AUTOSAR XML (schema 4-2-2)
package /STELLANTIS/EPT/ASWCs
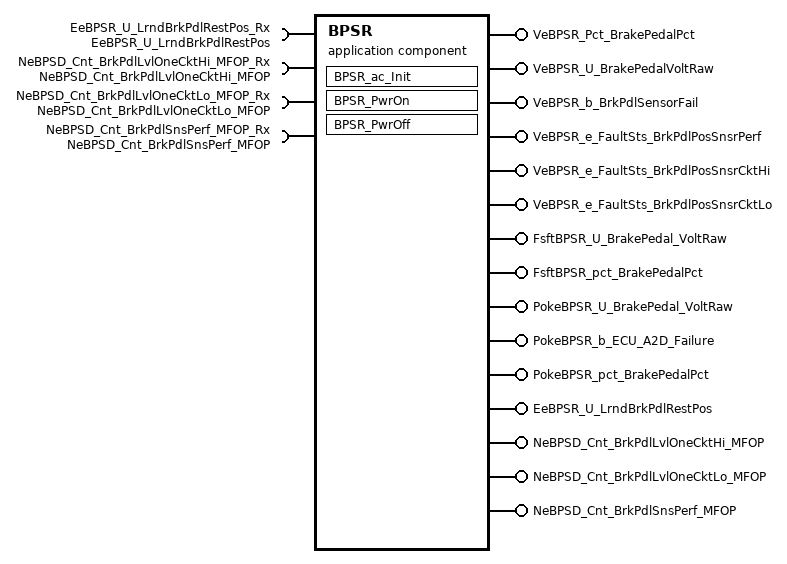
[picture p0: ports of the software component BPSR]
  application sw component type BPSR
    11 x provide port:
      VeBPSR_Pct_BrakePedalPct: nonqueued-sender-com-spec{data-element=Value, init-value=0}, provided-interface=VeBPSR_Pct_BrakePedalPct
      VeBPSR_U_BrakePedalVoltRaw: nonqueued-sender-com-spec{data-element=Value, init-value=0}, provided-interface=VeBPSR_U_BrakePedalVoltRaw
      VeBPSR_b_BrkPdlSensorFail: nonqueued-sender-com-spec{data-element=Value, init-value=0}, provided-interface=VeBPSR_b_BrkPdlSensorFail
      VeBPSR_e_FaultSts_BrkPdlPosSnsrPerf: nonqueued-sender-com-spec{data-element=Value, init-value=CeDFIB_e_Init}, provided-interface=VeBPSR_e_FaultSts_BrkPdlPosSnsrPerf
      VeBPSR_e_FaultSts_BrkPdlPosSnsrCktHi: nonqueued-sender-com-spec{data-element=Value, init-value=CeDFIB_e_Init}, provided-interface=VeBPSR_e_FaultSts_BrkPdlPosSnsrCktHi
      VeBPSR_e_FaultSts_BrkPdlPosSnsrCktLo: nonqueued-sender-com-spec{data-element=Value, init-value=CeDFIB_e_Init}, provided-interface=VeBPSR_e_FaultSts_BrkPdlPosSnsrCktLo
      FsftBPSR_U_BrakePedal_VoltRaw: server-com-spec=FsftBPSR_U_BrakePedal_VoltRaw, provided-interface=FsftBPSR_U_BrakePedal_VoltRaw
      FsftBPSR_pct_BrakePedalPct: server-com-spec=FsftBPSR_pct_BrakePedalPct, provided-interface=FsftBPSR_pct_BrakePedalPct
      PokeBPSR_U_BrakePedal_VoltRaw: server-com-spec{operation=PokeBPSR_U_BrakePedal_VoltRaw, queue-length=1}, provided-interface=PokeBPSR_U_BrakePedal_VoltRaw
      PokeBPSR_b_ECU_A2D_Failure: server-com-spec{operation=PokeBPSR_b_ECU_A2D_Failure, queue-length=1}, provided-interface=PokeBPSR_b_ECU_A2D_Failure
      PokeBPSR_pct_BrakePedalPct: server-com-spec{operation=PokeBPSR_pct_BrakePedalPct, queue-length=1}, provided-interface=PokeBPSR_pct_BrakePedalPct
    4 x require port:
      EeBPSR_U_LrndBrkPdlRestPos_Rx: nv-require-com-spec{init-value=20, variable=EeBPSR_U_LrndBrkPdlRestPos}, required-interface=EeBPSR_U_LrndBrkPdlRestPos
      NeBPSD_Cnt_BrkPdlLvlOneCktHi_MFOP_Rx: nv-require-com-spec{init-value=0, variable=NeBPSD_Cnt_BrkPdlLvlOneCktHi_MFOP}, required-interface=NeBPSD_Cnt_BrkPdlLvlOneCktHi_MFOP
      NeBPSD_Cnt_BrkPdlLvlOneCktLo_MFOP_Rx: nv-require-com-spec{init-value=0, variable=NeBPSD_Cnt_BrkPdlLvlOneCktLo_MFOP}, required-interface=NeBPSD_Cnt_BrkPdlLvlOneCktLo_MFOP
      NeBPSD_Cnt_BrkPdlSnsPerf_MFOP_Rx: nv-require-com-spec{init-value=0, variable=NeBPSD_Cnt_BrkPdlSnsPerf_MFOP}, required-interface=NeBPSD_Cnt_BrkPdlSnsPerf_MFOP
    4 x provide port:
      EeBPSR_U_LrndBrkPdlRestPos: nv-provide-com-spec{ram-block-init-value=20, variable=EeBPSR_U_LrndBrkPdlRestPos}, provided-interface=EeBPSR_U_LrndBrkPdlRestPos
      NeBPSD_Cnt_BrkPdlLvlOneCktHi_MFOP: nv-provide-com-spec{ram-block-init-value=0, variable=NeBPSD_Cnt_BrkPdlLvlOneCktHi_MFOP}, provided-interface=NeBPSD_Cnt_BrkPdlLvlOneCktHi_MFOP
      NeBPSD_Cnt_BrkPdlLvlOneCktLo_MFOP: nv-provide-com-spec{ram-block-init-value=0, variable=NeBPSD_Cnt_BrkPdlLvlOneCktLo_MFOP}, provided-interface=NeBPSD_Cnt_BrkPdlLvlOneCktLo_MFOP
      NeBPSD_Cnt_BrkPdlSnsPerf_MFOP: nv-provide-com-spec{ram-block-init-value=0, variable=NeBPSD_Cnt_BrkPdlSnsPerf_MFOP}, provided-interface=NeBPSD_Cnt_BrkPdlSnsPerf_MFOP
    behavior IB_BPSR: data-type-mapping=msADTtoIDTMapping, handle-termination-and-restart=NO-SUPPORT, included-data-type-set=data-type=TeBPSR_e_BrakeStatus
      init event Event_BPSR_ac_Init: start-on-event=BPSR_ac_Init
      init event Event_PwrOn: start-on-event=BPSR_PwrOn
      init event Event_PwrOff: start-on-event=BPSR_PwrOff
      runnable BPSR_ac_Init
        data-send-points:
          6 x access:
            OUT_VeBPSR_Pct_BrakePedalPct_Value: accessed-variable=VeBPSR_Pct_BrakePedalPct.Value
            OUT_VeBPSR_U_BrakePedalVoltRaw_Value: accessed-variable=VeBPSR_U_BrakePedalVoltRaw.Value
            OUT_VeBPSR_b_BrkPdlSensorFail_Value: accessed-variable=VeBPSR_b_BrkPdlSensorFail.Value
            OUT_VeBPSR_e_FaultSts_BrkPdlPosSnsrPerf_Value: accessed-variable=VeBPSR_e_FaultSts_BrkPdlPosSnsrPerf.Value
            OUT_VeBPSR_e_FaultSts_BrkPdlPosSnsrCktHi_Value: accessed-variable=VeBPSR_e_FaultSts_BrkPdlPosSnsrCktHi.Value
            OUT_VeBPSR_e_FaultSts_BrkPdlPosSnsrCktLo_Value: accessed-variable=VeBPSR_e_FaultSts_BrkPdlPosSnsrCktLo.Value
      runnable BPSR_PwrOn
        data-receive-point-by-arguments:
          4 x access:
            IN_EeBPSR_U_LrndBrkPdlRestPos_Rx_EeBPSR_U_LrndBrkPdlRestPos: accessed-variable=EeBPSR_U_LrndBrkPdlRestPos_Rx.EeBPSR_U_LrndBrkPdlRestPos
            IN_NeBPSD_Cnt_BrkPdlLvlOneCktHi_MFOP_Rx_NeBPSD_Cnt_BrkPdlLvlOneCktHi_MFOP: accessed-variable=NeBPSD_Cnt_BrkPdlLvlOneCktHi_MFOP_Rx.NeBPSD_Cnt_BrkPdlLvlOneCktHi_MFOP
            IN_NeBPSD_Cnt_BrkPdlLvlOneCktLo_MFOP_Rx_NeBPSD_Cnt_BrkPdlLvlOneCktLo_MFOP: accessed-variable=NeBPSD_Cnt_BrkPdlLvlOneCktLo_MFOP_Rx.NeBPSD_Cnt_BrkPdlLvlOneCktLo_MFOP
            IN_NeBPSD_Cnt_BrkPdlSnsPerf_MFOP_Rx_NeBPSD_Cnt_BrkPdlSnsPerf_MFOP: accessed-variable=NeBPSD_Cnt_BrkPdlSnsPerf_MFOP_Rx.NeBPSD_Cnt_BrkPdlSnsPerf_MFOP
        data-send-points:
          6 x access:
            OUT_VeBPSR_Pct_BrakePedalPct_Value: accessed-variable=VeBPSR_Pct_BrakePedalPct.Value
            OUT_VeBPSR_b_BrkPdlSensorFail_Value: accessed-variable=VeBPSR_b_BrkPdlSensorFail.Value
            OUT_VeBPSR_U_BrakePedalVoltRaw_Value: accessed-variable=VeBPSR_U_BrakePedalVoltRaw.Value
            OUT_VeBPSR_e_FaultSts_BrkPdlPosSnsrPerf_Value: accessed-variable=VeBPSR_e_FaultSts_BrkPdlPosSnsrPerf.Value
            OUT_VeBPSR_e_FaultSts_BrkPdlPosSnsrCktHi_Value: accessed-variable=VeBPSR_e_FaultSts_BrkPdlPosSnsrCktHi.Value
            OUT_VeBPSR_e_FaultSts_BrkPdlPosSnsrCktLo_Value: accessed-variable=VeBPSR_e_FaultSts_BrkPdlPosSnsrCktLo.Value
      runnable BPSR_PwrOff
        data-send-points:
          4 x access:
            OUT_EeBPSR_U_LrndBrkPdlRestPos_EeBPSR_U_LrndBrkPdlRestPos: accessed-variable=EeBPSR_U_LrndBrkPdlRestPos.EeBPSR_U_LrndBrkPdlRestPos
            OUT_NeBPSD_Cnt_BrkPdlLvlOneCktHi_MFOP_NeBPSD_Cnt_BrkPdlLvlOneCktHi_MFOP: accessed-variable=NeBPSD_Cnt_BrkPdlLvlOneCktHi_MFOP.NeBPSD_Cnt_BrkPdlLvlOneCktHi_MFOP
            OUT_NeBPSD_Cnt_BrkPdlLvlOneCktLo_MFOP_NeBPSD_Cnt_BrkPdlLvlOneCktLo_MFOP: accessed-variable=NeBPSD_Cnt_BrkPdlLvlOneCktLo_MFOP.NeBPSD_Cnt_BrkPdlLvlOneCktLo_MFOP
            OUT_NeBPSD_Cnt_BrkPdlSnsPerf_MFOP_NeBPSD_Cnt_BrkPdlSnsPerf_MFOP: accessed-variable=NeBPSD_Cnt_BrkPdlSnsPerf_MFOP.NeBPSD_Cnt_BrkPdlSnsPerf_MFOP
      variation point proxy Variant_BPSR_1: category=CONDITION, condition-access=0
